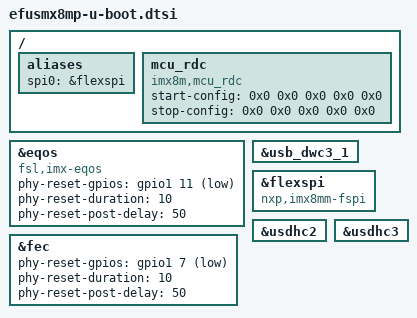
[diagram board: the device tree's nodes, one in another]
/*
* Copyright 2023 F&S Elektronik Systeme GmbH
*
* This program is free software; you can redistribute it and/or modify
* it under the terms of the GNU General Public License version 2 as
* published by the Free Software Foundation.
*
* This program is distributed in the hope that it will be useful,
* but WITHOUT ANY WARRANTY; without even the implied warranty of
* MERCHANTABILITY or FITNESS FOR A PARTICULAR PURPOSE.  See the
* GNU General Public License for more details.
*/

/ {
	aliases {
		spi0 = &flexspi;
	};

	mcu_rdc {
		compatible = "imx8m,mcu_rdc";
			    /* rdc config when MCU starts
			     * master
			     *   SDMA3p --> domain 1
			     *   SDMA3b --> domain 1
			     *   SDMA3_SPBA2  --> domain 1
			     * peripheral:
			     *   SAI3   --> Only Domain 1 can access
			     *   UART4  --> Only Domain 1 can access
			     *   GPT1   --> Only Domain 1 can access
			     *   SDMA3  --> Only Domain 1 can access
			     *   I2C3   --> Only Domain 1 can access
			     * memory:
			     *   TCM    --> Only Domain 1 can access (0x7E0000~0x81FFFF)
			     *   DDR    --> Only Domain 1 can access (0x80000000~0x81000000)
			     * end.
			     */

		start-config = <
#if 0 // ### Check if these settings are correct for F&S
			    RDC_MDA  RDC_MDA_SDMA3p DID1 0x0 0x0
			    RDC_MDA  RDC_MDA_SDMA3b DID1 0x0 0x0
			    RDC_MDA  RDC_MDA_SDMA3_SPBA2 DID1 0x0 0x0
			    RDC_PDAP RDC_PDAP_SAI3  PDAP_D1_ACCESS 0x0 0x0
			    RDC_PDAP RDC_PDAP_UART4 PDAP_D1_ACCESS 0x0 0x0
			    RDC_PDAP RDC_PDAP_GPT1  PDAP_D1_ACCESS 0x0 0x0
			    RDC_PDAP RDC_PDAP_SDMA3 PDAP_D1_ACCESS 0x0 0x0
			    RDC_PDAP RDC_PDAP_I2C3  PDAP_D1_ACCESS 0x0 0x0
			    RDC_MEM_REGION 22 TCM_START TCM_END MEM_D1_ACCESS
			    RDC_MEM_REGION 39 M4_DDR_START M4_DDR_END MEM_D1_ACCESS
#endif
			    0x0      0x0            0x0  0x0 0x0
			  >;
			    /* rdc config when MCU stops
			     * memory:
			     *   TCM    --> domain 0/1 can access (0x7E0000~0x81FFFF)
			     *   DDR    --> domain 0/1 can access (0x80000000~0x81000000)
			     * end.
			     */
		stop-config = <
#if 0 // ### Check if these settings are correct for F&S
			    RDC_MEM_REGION 22 TCM_START TCM_END MEM_D0D1_ACCESS
			    RDC_MEM_REGION 39 M4_DDR_START M4_DDR_END MEM_D0D1_ACCESS
#endif
			    0x0      0x0            0x0  0x0 0x0
			  >;
	};

};

&eqos {
	compatible = "fsl,imx-eqos";
	/delete-property/ assigned-clocks;
	/delete-property/ assigned-clock-parents;
	/delete-property/ assigned-clock-rates;
	
	phy-reset-gpios = <&gpio1 11 GPIO_ACTIVE_LOW>;
	phy-reset-duration = <10>;
	phy-reset-post-delay = <50>;
};

&fec {
	phy-reset-gpios = <&gpio1 7 GPIO_ACTIVE_LOW>;
	phy-reset-duration = <10>;
	phy-reset-post-delay = <50>;
};

&usb_dwc3_1 {
	/delete-property/ pinctrl-0;
	/delete-property/ extcon;
};

&flexspi {
	compatible = "nxp,imx8mm-fspi";
	reg-names = "fspi_base", "fspi_mmap";
	clock-names = "fspi", "fspi_en";
	status = "okay";
};

&usdhc2 {
	/delete-property/ vqmmc-supply;
};

&usdhc3 {
	/delete-property/ vqmmc-supply;
};

